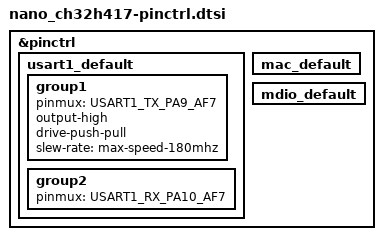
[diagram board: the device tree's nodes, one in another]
/*
 * Copyright (c) 2026 Liu Changjie
 *
 * SPDX-License-Identifier: Apache-2.0
 */

#include <zephyr/dt-bindings/pinctrl/ch32h41x-pinctrl.h>

&pinctrl {
	usart1_default: usart1_default {
		group1 {
			pinmux = <USART1_TX_PA9_AF7>;
			output-high;
			drive-push-pull;
			slew-rate = "max-speed-180mhz";
		};
		group2 {
			pinmux = <USART1_RX_PA10_AF7>;
		};
	};
	mac_default: mac_default {
		/* No pinmux required for internal PHY on the H417 */
	};

	mdio_default: mdio_default {
		/* No MDIO pinmux required for internal PHY */
	};
};
